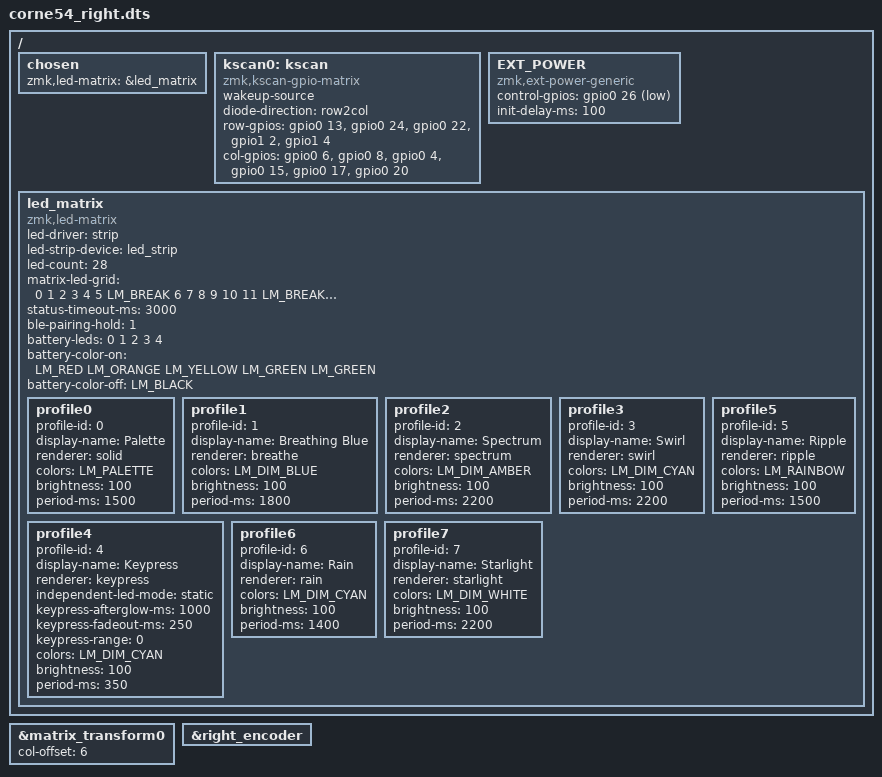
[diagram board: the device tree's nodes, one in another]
/*
*
* Copyright (c) 2023 The ZMK Contributors
* SPDX-License-Identifier: MIT
*
*/
#include <dt-bindings/zmk/ext_power.h>
#include <dt-bindings/led/led.h>
#include <dt-bindings/zmk/led_matrix.h>
#include <dt-bindings/zmk/led_matrix_colors.h>
#include "corne54.dtsi"
#include "corne54_right-pinctrl.dtsi"

/{
    chosen {
        zmk,led-matrix = &led_matrix;
    };

    kscan0: kscan {
        compatible = "zmk,kscan-gpio-matrix";
        wakeup-source;

        diode-direction = "row2col";
        row-gpios
            = <&gpio0 13 GPIO_ACTIVE_HIGH>
            , <&gpio0 24 GPIO_ACTIVE_HIGH>
            , <&gpio0 22 GPIO_ACTIVE_HIGH>
            , <&gpio1 2 GPIO_ACTIVE_HIGH>
            , <&gpio1 4 GPIO_ACTIVE_HIGH>
            ;

        col-gpios
            = <&gpio0 6  (GPIO_ACTIVE_HIGH | GPIO_PULL_DOWN)>
            , <&gpio0 8 (GPIO_ACTIVE_HIGH | GPIO_PULL_DOWN)>
            , <&gpio0 4 (GPIO_ACTIVE_HIGH | GPIO_PULL_DOWN)>
            , <&gpio0 15 (GPIO_ACTIVE_HIGH | GPIO_PULL_DOWN)>
            , <&gpio0 17 (GPIO_ACTIVE_HIGH | GPIO_PULL_DOWN)>
            , <&gpio0 20 (GPIO_ACTIVE_HIGH | GPIO_PULL_DOWN)>
            ;
    };

    // Node name must match original "EXT_POWER" label to preserve user settings.
    EXT_POWER {
        compatible = "zmk,ext-power-generic";
        control-gpios = <&gpio0 26 GPIO_ACTIVE_LOW>;
        init-delay-ms = <100>;
    };

    led_matrix: led_matrix {
        compatible = "zmk,led-matrix";
        led-driver = "strip";
        led-strip-device = <&led_strip>;
        led-count = <28>;
        matrix-led-grid = <
            0 1 2 3 4 5 LM_BREAK
            6 7 8 9 10 11 LM_BREAK
            12 13 14 15 16 17 LM_BREAK
            18 19 20 21 22 23 LM_BREAK
            27 24 25 26 LM_PH LM_PH
        >;
        status-timeout-ms = <3000>;
        ble-pairing-hold = <1>;

        battery-leds = <0 1 2 3 4>;
        battery-color-on = <LM_RED LM_ORANGE LM_YELLOW LM_GREEN LM_GREEN>;
        battery-color-off = <LM_BLACK>;

        profile0 {
            profile-id = <0>;
            display-name = "Palette";
            renderer = "solid";
            colors = <LM_PALETTE>;
            brightness = <100>;
            period-ms = <1500>;
        };

        profile1 {
            profile-id = <1>;
            display-name = "Breathing Blue";
            renderer = "breathe";
            colors = <LM_DIM_BLUE>;
            brightness = <100>;
            period-ms = <1800>;
        };

        profile2 {
            profile-id = <2>;
            display-name = "Spectrum";
            renderer = "spectrum";
            colors = <LM_DIM_AMBER>;
            brightness = <100>;
            period-ms = <2200>;
        };

        profile3 {
            profile-id = <3>;
            display-name = "Swirl";
            renderer = "swirl";
            colors = <LM_DIM_CYAN>;
            brightness = <100>;
            period-ms = <2200>;
        };

        profile4 {
			profile-id = <4>;
			display-name = "Keypress";
			renderer = "keypress";
			independent-led-mode = "static";
			keypress-afterglow-ms = <1000>;
			keypress-fadeout-ms = <250>;
			keypress-range = <0>;
			colors = <LM_DIM_CYAN>;
			brightness = <100>;
			period-ms = <350>;
        };

        profile5 {
            profile-id = <5>;
            display-name = "Ripple";
            renderer = "ripple";
            colors = <LM_RAINBOW>;
            brightness = <100>;
            period-ms = <1500>;
        };
        
        profile6 {
            profile-id = <6>;
            display-name = "Rain";
            renderer = "rain";
            colors = <LM_DIM_CYAN>;
            brightness = <100>;
            period-ms = <1400>;
        };

        profile7 {
            profile-id = <7>;
            display-name = "Starlight";
            renderer = "starlight";
            colors = <LM_DIM_WHITE>;
            brightness = <100>;
            period-ms = <2200>;
        };
    };

/*
     28 LEDs

     1  2  3  4  5  6
     7  8  9  10 11 12
     13 14 15 16 17 18
     19 20 21 22 23 24
     28 25 26 27
*/

};

&matrix_transform0 {
    col-offset = <6>;
};



&right_encoder {
    status = "okay";
};

/*
&i2c0 {
    compatible = "nordic,nrf-twi";
    pinctrl-0 = <&i2c0_default>;
    pinctrl-1 = <&i2c0_sleep>;
    pinctrl-names = "default", "sleep";
    //clock-frequency = <100000>;
    status = "okay";
    oled: ssd1306@3c {
        compatible = "solomon,ssd1306fb";
        reg = <0x3c>;
        width = <128>;
        height = <64>;
        segment-offset = <0>;
        page-offset = <0>;
        display-offset = <0>;
        multiplex-ratio = <63>;
        segment-remap;
        //com-invdir;
        //com-sequential;
        inversion-on;
        prechargep = <0x22>;
    };

};
*/
